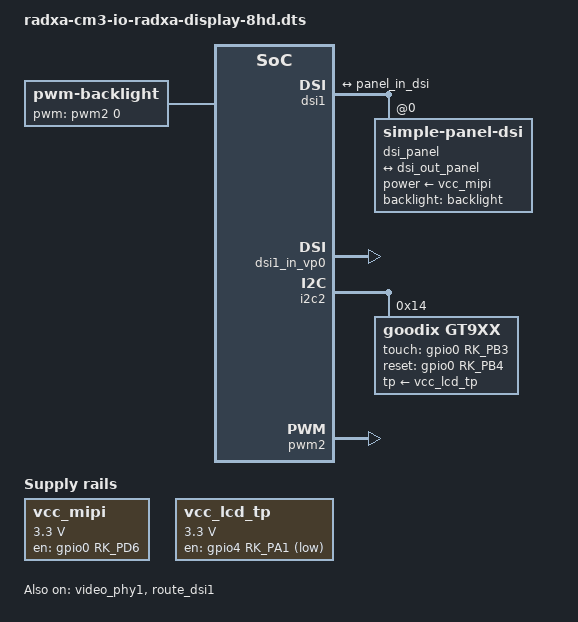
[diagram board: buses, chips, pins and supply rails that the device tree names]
/dts-v1/;
/plugin/;

#include <dt-bindings/gpio/gpio.h>
#include <dt-bindings/pinctrl/rockchip.h>
#include <dt-bindings/interrupt-controller/irq.h>
#include <dt-bindings/display/drm_mipi_dsi.h>

/ {
	metadata {
		title = "Enable Radxa Display 8HD";
		compatible = "radxa,cm3-io";
		category = "display";
		exclusive = "video_phy1", "dsi1";
		description = "Enable Radxa Display 8HD";
	};

	fragment@0 {
		target-path = "/";

		__overlay__ {
			vcc_mipi: vcc-mipi {
				status = "okay";
				compatible = "regulator-fixed";
				regulator-name = "vcc_mipi";
				regulator-min-microvolt = <3300000>;
				regulator-max-microvolt = <3300000>;
				pinctrl-names = "default";
				pinctrl-0 = <&vcc_mipi_pin>;
				gpio = <&gpio0 RK_PD6 GPIO_ACTIVE_HIGH>;
				enable-active-high;
				regulator-always-on;
				regulator-state-mem {
					regulator-off-in-suspend;
				};
			};

			vcc_lcd_tp: vcc-lcd-tp {
				status = "okay";
				compatible = "regulator-fixed";
				regulator-name = "vcc_lcd_tp";
				regulator-min-microvolt = <3300000>;
				regulator-max-microvolt = <3300000>;
				pinctrl-names = "default";
				pinctrl-0 = <&vcc_tp_pin>;
				gpio = <&gpio4 RK_PA1 GPIO_ACTIVE_LOW>;
				regulator-always-on;
				regulator-state-mem {
					regulator-off-in-suspend;
				};
			};

			backlight: backlight {
				status = "okay";
				compatible = "pwm-backlight";
				pinctrl-names = "default";
				pinctrl-0 = <&dsi1_backlight_en>;
				pwms = <&pwm2 0 25000 0>;
				brightness-levels = <
					255 254 253 252 251 250 249 248
					247 246 245 244 243 242 241 240
					239 238 237 236 235 234 233 232
					231 230 229 228 227 226 225 224
					223 222 221 220 219 218 217 216
					215 214 213 212 211 210 209 208
					207 206 205 204 203 202 201 200
					199 198 197 196 195 194 193 192
					191 190 189 188 187 186 185 184
					183 182 181 180 179 178 177 176
					175 174 173 172 171 170 169 168
					167 166 165 164 163 162 161 160
					159 158 157 156 155 154 153 152
					151 150 149 148 147 146 145 144
					143 142 141 140 139 138 137 136
					135 134 133 132 131 130 129 128
					127 126 125 124 123 122 121 120
					119 118 117 116 115 114 113 112
					111 110 109 108 107 106 105 104
					103 102 101 100  99  98  97  96
					95  94  93  92  91  90  89  88
					87  86  85  84  83  82  81  80
					79  78  77  76  75  74  73  72
					71  70  69  68  67  66  65  64
					63  62  61  60  59  58  57  56
					55  54  53  52  51  50  49  48
					47  46  45  44  43  42  41  40
					39  38  38  37  37  36  36  35
					35  34  34  33  33  32  32  31
					31  30  30  29  29  28  28  27
					27  26  26  25  25  24  24  23
					23  22  22  21  21  20  20   0
				>;
				default-brightness-level = <200>;
			};
		};
	};

	fragment@1 {
		target = <&dsi1>;

		__overlay__ {
			status = "okay";

			#address-cells = <1>;
			#size-cells = <0>;

			dsi_panel: panel@0 {
				status = "okay";
				compatible = "simple-panel-dsi";
				reg = <0>;
				backlight = <&backlight>;
				power-supply = <&vcc_mipi>;
				pinctrl-names = "default";
				pinctrl-0 = <&dsi1_lcd_rst_gpio>;

				width-mm = <107>;
				height-mm = <199>;
				dsi,flags = <(MIPI_DSI_MODE_VIDEO | MIPI_DSI_MODE_VIDEO_BURST | MIPI_DSI_MODE_LPM | MIPI_DSI_MODE_EOT_PACKET)>;
				dsi,format = <MIPI_DSI_FMT_RGB888>;
				dsi,lanes  = <2>;
				panel-init-sequence = [
					15 00 02 E0 00
					15 00 02 E1 93
					15 00 02 E2 65
					15 00 02 E3 F8
					15 00 02 80 03
					15 00 02 E0 01
					15 00 02 00 00
					15 00 02 01 72
					15 00 02 03 00
					15 00 02 04 65
					15 00 02 0C 74
					15 00 02 17 00
					15 00 02 18 B7
					15 00 02 19 00
					15 00 02 1A 00
					15 00 02 1B B7
					15 00 02 1C 00
					15 00 02 24 FE
					15 00 02 37 19
					15 00 02 38 05
					15 00 02 39 00
					15 00 02 3A 01
					15 00 02 3B 01
					15 00 02 3C 70
					15 00 02 3D FF
					15 00 02 3E FF
					15 00 02 3F FF
					15 00 02 40 06
					15 00 02 41 A0
					15 00 02 43 1E
					15 00 02 44 0F
					15 00 02 45 28
					15 00 02 4B 04
					15 00 02 55 02
					15 00 02 56 01
					15 00 02 57 A9
					15 00 02 58 0A
					15 00 02 59 0A
					15 00 02 5A 37
					15 00 02 5B 19
					15 00 02 5D 78
					15 00 02 5E 63
					15 00 02 5F 54
					15 00 02 60 48
					15 00 02 61 45
					15 00 02 62 38
					15 00 02 63 3D
					15 00 02 64 28
					15 00 02 65 43
					15 00 02 66 41
					15 00 02 67 43
					15 00 02 68 62
					15 00 02 69 50
					15 00 02 6A 57
					15 00 02 6B 49
					15 00 02 6C 44
					15 00 02 6D 37
					15 00 02 6E 23
					15 00 02 6F 10
					15 00 02 70 78
					15 00 02 71 63
					15 00 02 72 54
					15 00 02 73 49
					15 00 02 74 45
					15 00 02 75 38
					15 00 02 76 3D
					15 00 02 77 28
					15 00 02 78 43
					15 00 02 79 41
					15 00 02 7A 43
					15 00 02 7B 62
					15 00 02 7C 50
					15 00 02 7D 57
					15 00 02 7E 49
					15 00 02 7F 44
					15 00 02 80 37
					15 00 02 81 23
					15 00 02 82 10
					15 00 02 E0 02
					15 00 02 00 47
					15 00 02 01 47
					15 00 02 02 45
					15 00 02 03 45
					15 00 02 04 4B
					15 00 02 05 4B
					15 00 02 06 49
					15 00 02 07 49
					15 00 02 08 41
					15 00 02 09 1F
					15 00 02 0A 1F
					15 00 02 0B 1F
					15 00 02 0C 1F
					15 00 02 0D 1F
					15 00 02 0E 1F
					15 00 02 0F 5F
					15 00 02 10 5F
					15 00 02 11 57
					15 00 02 12 77
					15 00 02 13 35
					15 00 02 14 1F
					15 00 02 15 1F
					15 00 02 16 46
					15 00 02 17 46
					15 00 02 18 44
					15 00 02 19 44
					15 00 02 1A 4A
					15 00 02 1B 4A
					15 00 02 1C 48
					15 00 02 1D 48
					15 00 02 1E 40
					15 00 02 1F 1F
					15 00 02 20 1F
					15 00 02 21 1F
					15 00 02 22 1F
					15 00 02 23 1F
					15 00 02 24 1F
					15 00 02 25 5F
					15 00 02 26 5F
					15 00 02 27 57
					15 00 02 28 77
					15 00 02 29 35
					15 00 02 2A 1F
					15 00 02 2B 1F
					15 00 02 58 40
					15 00 02 59 00
					15 00 02 5A 00
					15 00 02 5B 10
					15 00 02 5C 06
					15 00 02 5D 40
					15 00 02 5E 01
					15 00 02 5F 02
					15 00 02 60 30
					15 00 02 61 01
					15 00 02 62 02
					15 00 02 63 03
					15 00 02 64 6B
					15 00 02 65 05
					15 00 02 66 0C
					15 00 02 67 73
					15 00 02 68 09
					15 00 02 69 03
					15 00 02 6A 56
					15 00 02 6B 08
					15 00 02 6C 00
					15 00 02 6D 04
					15 00 02 6E 04
					15 00 02 6F 88
					15 00 02 70 00
					15 00 02 71 00
					15 00 02 72 06
					15 00 02 73 7B
					15 00 02 74 00
					15 00 02 75 F8
					15 00 02 76 00
					15 00 02 77 D5
					15 00 02 78 2E
					15 00 02 79 12
					15 00 02 7A 03
					15 00 02 7B 00
					15 00 02 7C 00
					15 00 02 7D 03
					15 00 02 7E 7B
					15 00 02 E0 04
					15 00 02 00 0E
					15 00 02 02 B3
					15 00 02 09 60
					15 00 02 0E 2A
					15 00 02 36 59
					15 00 02 E0 00
					15 00 02 80 01
					15 00 02 E0 00
					15 00 02 11 00
					15 78 02 29 00
				];
 
				panel-exit-sequence = [
					05 00 01 28
					05 00 01 10
				];
 
				disp_timings0: display-timings {
					native-mode = <&dsi0_timing0>;
					dsi0_timing0: timing0 {
						clock-frequency = <70000000>;
						hactive = <800>;
						vactive = <1280>;
						hsync-len = <20>;
						hback-porch = <20>;
						hfront-porch = <40>;
						vsync-len = <4>;
						vback-porch = <28>;
						vfront-porch = <30>;
						hsync-active = <0>;
						vsync-active = <0>;
						de-active = <0>;
						pixelclk-active = <0>;
					};
				};

				ports {
					#address-cells = <1>;
					#size-cells = <0>;
					port@0 {
						reg = <0>;
						panel_in_dsi: endpoint {
							remote-endpoint = <&dsi_out_panel>;
						};
					};
				};
			};

			ports {
				#address-cells = <1>;
				#size-cells = <0>;

				port@1 {
					reg = <1>;
					dsi_out_panel: endpoint {
						remote-endpoint = <&panel_in_dsi>;
					};
				};
			};
		};
	};

	fragment@2 {
		target = <&dsi1_in_vp0>;

		__overlay__ {
			status = "okay";
		};
	};

	fragment@3 {
		target = <&video_phy1>;

		__overlay__ {
			status = "okay";
		};
	};

	fragment@4 {
		target = <&hdmi_in_vp0>;

		__overlay__ {
			status = "disabled";
		};
	};

	fragment@5 {
		target = <&hdmi>;

		__overlay__ {
			status = "disabled";
		};
	};

	fragment@6 {
		target = <&route_dsi1>;

		__overlay__ {
			status = "okay";
			connect = <&vp0_out_dsi1>;
		};
	};

	fragment@7 {
		target = <&i2c2>;

		__overlay__ {
			status = "okay";
			pinctrl-0 = <&i2c2m1_xfer>;
			#address-cells = <1>;
			#size-cells = <0>;

			gt9xx: gt9xx@14 {
				status = "okay";
				compatible = "goodix,gt9xx";
				reg = <0x14>;
				pinctrl-names = "default";
				pinctrl-0 = <&gt9xx_gpio>;
				touch-gpio = <&gpio0 RK_PB3 IRQ_TYPE_LEVEL_HIGH>;
				reset-gpio = <&gpio0 RK_PB4 GPIO_ACTIVE_HIGH>;
				max-x = <800>;
				max-y = <1280>;
				tp-size = <9112>;
				tp-supply = <&vcc_lcd_tp>;
			};
		};
	};

	fragment@8 {
		target = <&pwm2>;

		__overlay__ {
			status = "okay";
		};
	};

	fragment@9 {
		target = <&pinctrl>;

		__overlay__ {
			gt9xx {
				gt9xx_gpio: gt9xx-gpio {
					rockchip,pins =
						<0 RK_PB3 RK_FUNC_GPIO &pcfg_pull_none>,
						<0 RK_PB4 RK_FUNC_GPIO &pcfg_pull_up>;
				};
			};

			lcd-vcc {
				vcc_mipi_pin: vcc-mipi-pin {
					rockchip,pins = <0 RK_PD6 RK_FUNC_GPIO &pcfg_pull_up>;
				};

				vcc_tp_pin: vcc-tp-pin {
					rockchip,pins = <4 RK_PA1 RK_FUNC_GPIO &pcfg_pull_down>;
				};
			};

			dsi1-lcd {
				dsi1_lcd_rst_gpio: dsi1-lcd-rst-gpio {
					rockchip,pins = <4 RK_PA0 RK_FUNC_GPIO &pcfg_pull_up>;
				};

				dsi1_backlight_en: dsi1-backlight-en {
					rockchip,pins = <3 RK_PD7 RK_FUNC_GPIO &pcfg_pull_up>;
				};
			};
		};
	};
};
